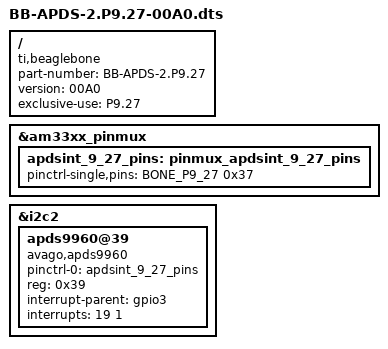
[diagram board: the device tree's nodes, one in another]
/*
 * Copyright (C) 2015 Robert Nelson <robertcnelson@gmail.com>
 *
 * Virtual cape for onewire on connector pin P9.12
 *
 * This program is free software; you can redistribute it and/or modify
 * it under the terms of the GNU General Public License version 2 as
 * published by the Free Software Foundation.
 */
/dts-v1/;
/plugin/;

#include <dt-bindings/board/am335x-bbw-bbb-base.h>
#include <dt-bindings/gpio/gpio.h>
#include <dt-bindings/pinctrl/am33xx.h>
#include <dt-bindings/interrupt-controller/irq.h>

/ {
	compatible = "ti,beaglebone", "ti,beaglebone-black", "ti,beaglebone-green";

	/* identification */
	part-number = "BB-APDS-2.P9.27";
	version = "00A0";

	/* state the resources this cape uses */
	exclusive-use =
		/* the pin header uses */
		"P9.27";

	fragment@0 {
		target = <&am33xx_pinmux>;
		__overlay__ {
			apdsint_9_27_pins: pinmux_apdsint_9_27_pins {
				pinctrl-single,pins = < BONE_P9_27 0x37 >;
			};
		};
	};

	fragment@1 {
		target = <&i2c2>;
		__overlay__ {
		    #address-cells = <1>;
		    #size-cells = <0>;
		    apds9960@39 {
				status = "okay";
				pinctrl-names = "default";
				pinctrl-0 = <&apdsint_9_27_pins>;

				compatible = "avago,apds9960";
				reg = <0x39>;
				interrupt-parent = <&gpio3>;
				interrupts = <19 1 /*IRQ_TYPE_EDGE_RISING*/>;
		    };
		};
	};
};
